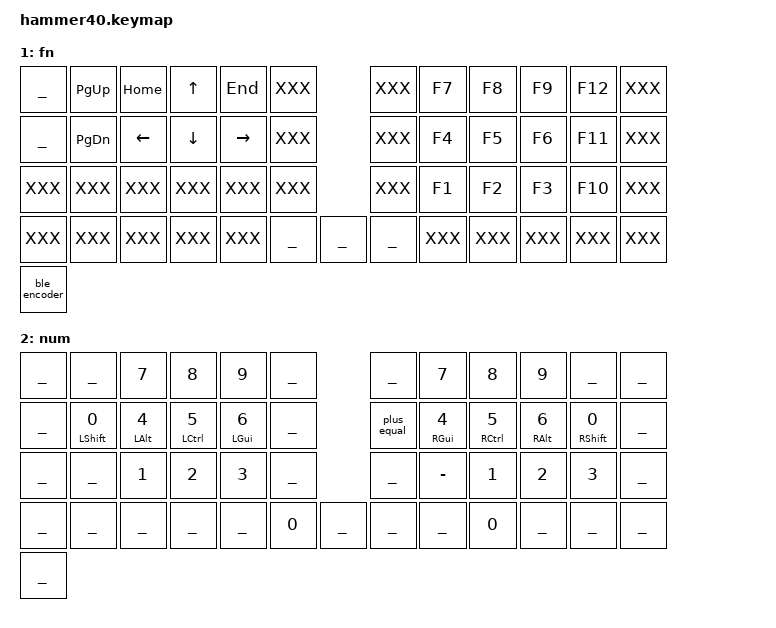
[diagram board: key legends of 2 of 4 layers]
/*
 * Copyright (c) 2020 The ZMK Contributors
 *
 * SPDX-License-Identifier: MIT
 */

#include <behaviors.dtsi>
#include <dt-bindings/zmk/keys.h>
#include <dt-bindings/zmk/bt.h>
#include <dt-bindings/zmk/outputs.h>

#include "hammer40_keylabels.h"
#include "zmk-helpers/helper.h"
#include "zmk-helpers/unicode-chars/currency.dtsi"

/* Layers */
#define DEF 0
#define FN 1
#define NUM 2
#define SYS 3

#include "behave.dtsi"

/* Custom behaviors */

/ {
    behaviors {
        ble_encoder: ble_encoder {
            compatible = "zmk,behavior-sensor-rotate";
            #sensor-binding-cells = <0>;
            bindings = <&bt BT_NXT>, <&bt BT_PRV>;
        };
    };
};

// tap: play/pause | double-tap: media next | triple-tap: media previous
ZMK_TAP_DANCE(rot_td,
    tapping-term-ms = <250>;
    bindings = <&kp C_PP>, <&kp C_NEXT>, <&kp C_PREV>;
)


#undef COMBO_HOOK
#define COMBO_HOOK require-prior-idle-ms = <150>;
#define COMBO_TERM_FAST 25
#define COMBO_TERM_SLOW 50


// left and right bracket [ ]
ZMK_COMBO(lbkt, &kp LBKT, RT1 RT2, DEF, COMBO_TERM_FAST)
ZMK_COMBO(rbkt, &kp RBKT, RT2 RT3, DEF, COMBO_TERM_FAST)

// left and right parenthesis ( )
ZMK_COMBO(lpar, &kp LPAR, RM1 RM2, DEF NUM, COMBO_TERM_FAST)
ZMK_COMBO(rpar, &kp RPAR, RM2 RM3, DEF NUM, COMBO_TERM_FAST)

// apostrophe
ZMK_COMBO(apos, &kp APOS, RM3 RM4, DEF NUM, COMBO_TERM_FAST)

// left and right less-then and greater-then < >
ZMK_COMBO(lt, &kp LT, LT3 LT2, DEF, COMBO_TERM_FAST)
ZMK_COMBO(gt, &kp GT, LT2 LT1, DEF, COMBO_TERM_FAST)

// minus and equal - =
ZMK_COMBO(minus, &kp MINUS, RB1 RB2, DEF NUM, COMBO_TERM_FAST)
ZMK_COMBO(equal, &kp EQUAL, RB2 RB3, DEF NUM, COMBO_TERM_FAST)

/* Keymap */

ZMK_CONDITIONAL_LAYER(sys, FN NUM, SYS)  // FN + NUM --> SYS

ZMK_LAYER(base,
//╭─────────────┬─────────────┬─────────────┬─────────────┬─────────────┬─────────────╮             ╭─────────────┬─────────────┬─────────────┬─────────────┬─────────────┬─────────────╮
    &kp GRAVE     &kp Q         &kp W         &kp E         &kp R         &kp T                       &kp Y         &kp U         &kp I         &kp O         &kp P           &kp MINUS 
//├─────────────┼─────────────┼─────────────┼─────────────┼─────────────┼─────────────┤             ├─────────────┼─────────────┼─────────────┼─────────────┼─────────────┼─────────────┤
    &kp ESC       &hml LSHFT A   &hml LALT S  &hml LCTRL D  &hml LGUI F      &kp G                       &kp H     &hmr RGUI J  &hmr RCTRL K   &hmr RALT L   &hmr RSHFT SEMI   &kp APOS
//├─────────────┼─────────────┼─────────────┼─────────────┼─────────────┼─────────────┤ ╭─────────╮ ├─────────────┼─────────────┼─────────────┼─────────────┼─────────────┼─────────────┤
    &kp RBKT      &kp Z         &kp X         &kp C         &kp V         &kp B          &rot_td      &kp N         &kp M         &kp COMMA     &kp DOT       &kp FSLH        &kp RSHFT 
//├─────────────┼─────────────┼─────────────┼─────────────┼─────────────┼─────────────┼─────────────┼─────────────┼─────────────┼─────────────┼─────────────┼─────────────┼─────────────┤
     ___           ___           ___            &kp ESC    &kp SPACE     &smart_tab          ___      &lt FN ENTER   &bs_del       &sk LSHFT        ___           ___         ___ 
//╰─────────────┴─────────────┴─────────────┴─────────────┴─────────────┴─────────────┴─────────────┴─────────────┴─────────────┴─────────────┴─────────────┴─────────────┴─────────────╯ 
    , &inc_dec_kp C_VOL_UP C_VOL_DN
)

ZMK_LAYER(fn,
//╭─────────────┬─────────────┬─────────────┬─────────────┬─────────────┬─────────────╮             ╭─────────────┬─────────────┬─────────────┬─────────────┬─────────────┬─────────────╮
    ___            &kp PG_UP     &kp HOME      &kp UP        &kp END       XXX                           XXX           &kp F7        &kp F8        &kp F9        &kp F12       XXX
//├─────────────┼─────────────┼─────────────┼─────────────┼─────────────┼─────────────┤             ├─────────────┼─────────────┼─────────────┼─────────────┼─────────────┼─────────────┤
    ___           &kp PG_DN     &kp LEFT      &kp DOWN      &kp RIGHT     XXX                         XXX              &kp F4        &kp F5        &kp F6        &kp F11       XXX
//├─────────────┼─────────────┼─────────────┼─────────────┼─────────────┼─────────────┤ ╭─────────╮ ├─────────────┼─────────────┼─────────────┼─────────────┼─────────────┼─────────────┤
    XXX           XXX           XXX           XXX           XXX           XXX                         XXX           &kp F1        &kp F2        &kp F3        &kp F10       XXX
//├─────────────┼─────────────┼─────────────┼─────────────┼─────────────┼─────────────┼─────────────┼─────────────┼─────────────┼─────────────┼─────────────┼─────────────┼─────────────┤
    XXX           XXX           XXX           XXX           XXX           ___              ___        ___           XXX           XXX           XXX           XXX           XXX
//╰─────────────┴─────────────┴─────────────┴─────────────┴─────────────┴─────────────┴─────────────┴─────────────┴─────────────┴─────────────┴─────────────┴─────────────┴─────────────╯ 
    , &ble_encoder
)

ZMK_LAYER(num,
//╭─────────────┬─────────────┬─────────────┬─────────────┬─────────────┬─────────────╮             ╭─────────────┬─────────────┬─────────────┬─────────────┬─────────────┬─────────────╮
    ___              ___           &kp N7        &kp N8        &kp N9        ___                         ___           &kp N7        &kp N8        &kp N9       ___                ___
//├─────────────┼─────────────┼─────────────┼─────────────┼─────────────┼─────────────┤             ├─────────────┼─────────────┼─────────────┼─────────────┼─────────────┼─────────────┤
    ___           &hml LSHFT N0  &hml LALT N4  &hml LCTRL N5 &hml LGUI N6  ___                         &plus_equal           &hmr RGUI N4  &hmr RCTRL N5 &hmr RALT N6  &hmr RSHFT N0      ___
//├─────────────┼─────────────┼─────────────┼─────────────┼─────────────┼─────────────┤ ╭─────────╮ ├─────────────┼─────────────┼─────────────┼─────────────┼─────────────┼─────────────┤
    ___           ___            &kp N1        &kp N2        &kp N3        ___              ___        &kp MINUS           &kp N1        &kp N2        &kp N3        ___                 ___
//├─────────────┼─────────────┼─────────────┼─────────────┼─────────────┼─────────────┼─────────────┼─────────────┼─────────────┼─────────────┼─────────────┼─────────────┼─────────────┤
    ___           ___           ___           ___           &kp N0            ___              ___       ___           &kp N0            ___           ___           ___                 ___
//╰─────────────┴─────────────┴─────────────┴─────────────┴─────────────┴─────────────┴─────────────┴─────────────┴─────────────┴─────────────┴─────────────┴─────────────┴─────────────╯ 
)

ZMK_LAYER(sys,
//╭─────────────┬─────────────┬─────────────┬─────────────┬─────────────┬─────────────╮             ╭─────────────┬─────────────┬─────────────┬─────────────┬─────────────┬─────────────╮
    BLE_C(0)      BLE_C(1)      BLE_C(2)      BLE_C(3)      BLE_C(4)      &bt BT_CLR                  &bt BT_CLR_ALL BLE_D(4)     BLE_D(3)      BLE_D(2)      BLE_D(1)      BLE_D(0)
//├─────────────┼─────────────┼─────────────┼─────────────┼─────────────┼─────────────┤             ├─────────────┼─────────────┼─────────────┼─────────────┼─────────────┼─────────────┤
    ___           ___           ___           ___           &soft_off     &bootloader                 &bootloader    &soft_off    ___           ___
//├─────────────┼─────────────┼─────────────┼─────────────┼─────────────┼─────────────┤ ╭─────────╮ ├─────────────┼─────────────┼─────────────┼─────────────┼─────────────┼─────────────┤
    ___           ___           ___           ___           ___           &sys_reset        ___       &sys_reset     ___          ___           ___           ___           ___
//├─────────────┼─────────────┼─────────────┼─────────────┼─────────────┼─────────────┼─────────────┼─────────────┼─────────────┼─────────────┼─────────────┼─────────────┼─────────────┤
    &out OUT_BLE  &out OUT_USB  ___           ___           ___           ___               ___       ___            ___          ___           ___           &out OUT_USB  &out OUT_BLE
//╰─────────────┴─────────────┴─────────────┴─────────────┴─────────────┴─────────────┴─────────────┴─────────────┴─────────────┴─────────────┴─────────────┴─────────────┴─────────────╯ 
    , &ble_encoder
)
